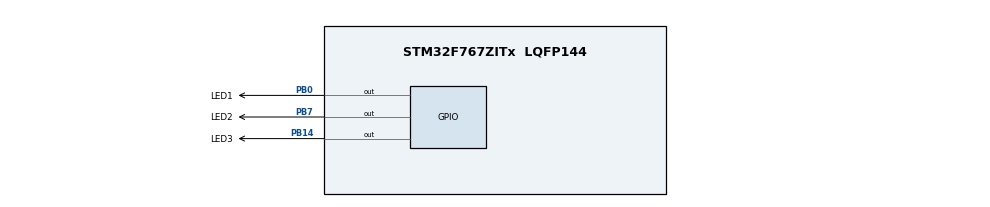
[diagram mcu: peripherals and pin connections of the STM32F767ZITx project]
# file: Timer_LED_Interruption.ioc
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CORTEX_M7.default_mode_Activation=1
Mcu.Family=STM32F7
Mcu.Name=STM32F767ZITx
Mcu.Package=LQFP144
NVIC.PriorityGroup=NVIC_PRIORITYGROUP_4
NVIC.TIM3_IRQn=true\:0\:0\:false\:false\:true\:true\:true\:true
PB0.GPIO_Label=LED1
PB0.Signal=GPIO_Output
PB14.GPIO_Label=LED3
PB14.Signal=GPIO_Output
PB7.GPIO_Label=LED2
PB7.Signal=GPIO_Output
ProjectManager.HeapSize=0x200
ProjectManager.StackSize=0x400
ProjectManager.TargetToolchain=STM32CubeIDE
RCC.HSE_VALUE=25000000
RCC.HSI_VALUE=16000000
RCC.LSE_VALUE=32768
RCC.USBFreq_Value=96000000
RCC.VCOOutputFreq_Value=192000000
TIM3.Period=2000
TIM3.Prescaler=16000
VP_TIM3_VS_ClockSourceINT.Mode=Internal
board=custom

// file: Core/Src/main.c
/* USER CODE BEGIN Header */
/**
  ******************************************************************************
  * @file           : main.c
  * @brief          : Main program body
  ******************************************************************************
  * @attention
  *
  * Copyright (c) 2025 STMicroelectronics.
  * All rights reserved.
  *
  * This software is licensed under terms that can be found in the LICENSE file
  * in the root directory of this software component.
  * If no LICENSE file comes with this software, it is provided AS-IS.
  *
  ******************************************************************************
  */
/* USER CODE END Header */
#include "main.h"

TIM_HandleTypeDef htim3;

void SystemClock_Config(void);
static void MPU_Config(void);
static void MX_GPIO_Init(void);
static void MX_TIM3_Init(void);

/* USER CODE BEGIN 0 */
/* Private variables */
uint32_t counter = 0;

void HAL_TIM_PeriodElapsedCallback(TIM_HandleTypeDef *htim)
{
    if(htim->Instance == TIM3)
    {
        // Toggle LED every 2 seconds because: Core is operating at up to 216 MHz frequency.
    	// Period = 16 000 means
    	// Timer3 frequency = 16 000 000 / 16 000 = 1000 iterations / 1sec
    	// To calculate 2 seconds we need 1000 * 2 = 2000 specify as htim3.Init.Period

        HAL_GPIO_TogglePin(LED3_GPIO_Port,LED3_Pin);
        HAL_GPIO_TogglePin(LED2_GPIO_Port,LED2_Pin);
        HAL_GPIO_TogglePin(LED1_GPIO_Port,LED1_Pin);
    }
}
/* USER CODE END 0 */

int main(void)
{

  /* MPU Configuration--------------------------------------------------------*/
  MPU_Config();

  /* MCU Configuration--------------------------------------------------------*/

  /* Reset of all peripherals, Initializes the Flash interface and the Systick. */
  HAL_Init();

  /* Configure the system clock */
  SystemClock_Config();

  /* Initialize all configured peripherals */
  MX_GPIO_Init();
  MX_TIM3_Init();
  /* USER CODE BEGIN 2 */
  HAL_TIM_Base_Start_IT(&htim3);
  /* USER CODE END 2 */

  /* Infinite loop */
  while (1)
  {

  }
}

void SystemClock_Config(void)
{
  RCC_OscInitTypeDef RCC_OscInitStruct = {0};
  RCC_ClkInitTypeDef RCC_ClkInitStruct = {0};

  /** Configure the main internal regulator output voltage
  */
  __HAL_RCC_PWR_CLK_ENABLE();
  __HAL_PWR_VOLTAGESCALING_CONFIG(PWR_REGULATOR_VOLTAGE_SCALE3);

  /** Initializes the RCC Oscillators according to the specified parameters
  * in the RCC_OscInitTypeDef structure.
  */
  RCC_OscInitStruct.OscillatorType = RCC_OSCILLATORTYPE_HSI;
  RCC_OscInitStruct.HSIState = RCC_HSI_ON;
  RCC_OscInitStruct.HSICalibrationValue = RCC_HSICALIBRATION_DEFAULT;
  RCC_OscInitStruct.PLL.PLLState = RCC_PLL_NONE;
  if (HAL_RCC_OscConfig(&RCC_OscInitStruct) != HAL_OK)
  {
    Error_Handler();
  }

  /** Initializes the CPU, AHB and APB buses clocks
  */
  RCC_ClkInitStruct.ClockType = RCC_CLOCKTYPE_HCLK|RCC_CLOCKTYPE_SYSCLK
                              |RCC_CLOCKTYPE_PCLK1|RCC_CLOCKTYPE_PCLK2;
  RCC_ClkInitStruct.SYSCLKSource = RCC_SYSCLKSOURCE_HSI;
  RCC_ClkInitStruct.AHBCLKDivider = RCC_SYSCLK_DIV1;
  RCC_ClkInitStruct.APB1CLKDivider = RCC_HCLK_DIV1;
  RCC_ClkInitStruct.APB2CLKDivider = RCC_HCLK_DIV1;

  if (HAL_RCC_ClockConfig(&RCC_ClkInitStruct, FLASH_LATENCY_0) != HAL_OK)
  {
    Error_Handler();
  }
}

static void MX_TIM3_Init(void)
{

  TIM_ClockConfigTypeDef sClockSourceConfig = {0};
  TIM_MasterConfigTypeDef sMasterConfig = {0};

  htim3.Instance = TIM3;
  htim3.Init.Prescaler = 16000;
  htim3.Init.CounterMode = TIM_COUNTERMODE_UP;
  htim3.Init.Period = 2000;
  htim3.Init.ClockDivision = TIM_CLOCKDIVISION_DIV1;
  htim3.Init.AutoReloadPreload = TIM_AUTORELOAD_PRELOAD_DISABLE;
  if (HAL_TIM_Base_Init(&htim3) != HAL_OK)
  {
    Error_Handler();
  }
  sClockSourceConfig.ClockSource = TIM_CLOCKSOURCE_INTERNAL;
  if (HAL_TIM_ConfigClockSource(&htim3, &sClockSourceConfig) != HAL_OK)
  {
    Error_Handler();
  }
  sMasterConfig.MasterOutputTrigger = TIM_TRGO_RESET;
  sMasterConfig.MasterSlaveMode = TIM_MASTERSLAVEMODE_DISABLE;
  if (HAL_TIMEx_MasterConfigSynchronization(&htim3, &sMasterConfig) != HAL_OK)
  {
    Error_Handler();
  }

}

static void MX_GPIO_Init(void)
{
  GPIO_InitTypeDef GPIO_InitStruct = {0};

  /* GPIO Ports Clock Enable */
  __HAL_RCC_GPIOB_CLK_ENABLE();

  /*Configure GPIO pin Output Level */
  HAL_GPIO_WritePin(GPIOB, LED1_Pin|LED3_Pin|LED2_Pin, GPIO_PIN_RESET);

  /*Configure GPIO pins : LED1_Pin LED3_Pin LED2_Pin */
  GPIO_InitStruct.Pin = LED1_Pin|LED3_Pin|LED2_Pin;
  GPIO_InitStruct.Mode = GPIO_MODE_OUTPUT_PP;
  GPIO_InitStruct.Pull = GPIO_NOPULL;
  GPIO_InitStruct.Speed = GPIO_SPEED_FREQ_LOW;
  HAL_GPIO_Init(GPIOB, &GPIO_InitStruct);

}

 /* MPU Configuration */

void MPU_Config(void)
{
  MPU_Region_InitTypeDef MPU_InitStruct = {0};

  /* Disables the MPU */
  HAL_MPU_Disable();

  /** Initializes and configures the Region and the memory to be protected
  */
  MPU_InitStruct.Enable = MPU_REGION_ENABLE;
  MPU_InitStruct.Number = MPU_REGION_NUMBER0;
  MPU_InitStruct.BaseAddress = 0x0;
  MPU_InitStruct.Size = MPU_REGION_SIZE_4GB;
  MPU_InitStruct.SubRegionDisable = 0x87;
  MPU_InitStruct.TypeExtField = MPU_TEX_LEVEL0;
  MPU_InitStruct.AccessPermission = MPU_REGION_NO_ACCESS;
  MPU_InitStruct.DisableExec = MPU_INSTRUCTION_ACCESS_DISABLE;
  MPU_InitStruct.IsShareable = MPU_ACCESS_SHAREABLE;
  MPU_InitStruct.IsCacheable = MPU_ACCESS_NOT_CACHEABLE;
  MPU_InitStruct.IsBufferable = MPU_ACCESS_NOT_BUFFERABLE;

  HAL_MPU_ConfigRegion(&MPU_InitStruct);
  /* Enables the MPU */
  HAL_MPU_Enable(MPU_PRIVILEGED_DEFAULT);

}

void Error_Handler(void)
{
  __disable_irq();
  while (1)
  {
  }
}
